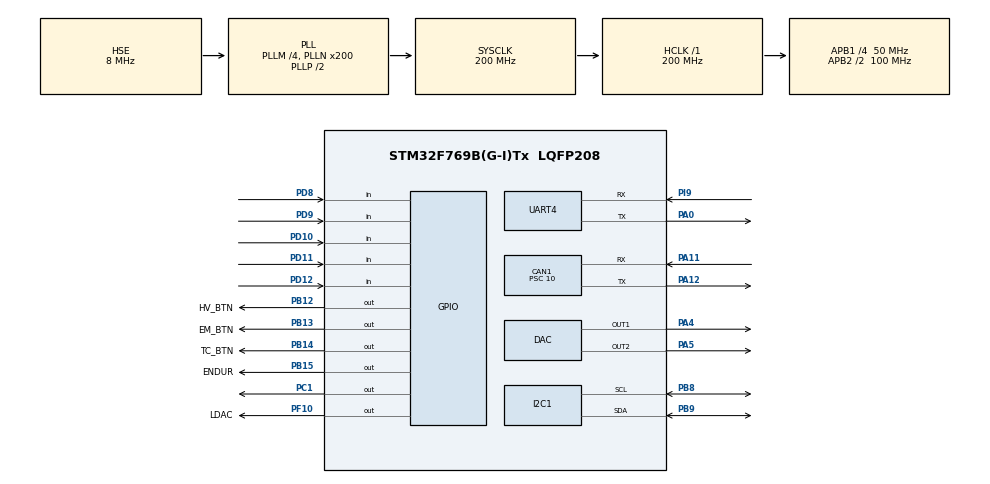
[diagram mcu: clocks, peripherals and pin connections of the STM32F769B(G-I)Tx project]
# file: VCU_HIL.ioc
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CAN1.ABOM=ENABLE
CAN1.AWUM=ENABLE
CAN1.BS1=CAN_BS1_8TQ
CAN1.CalculateBaudRate=500000
CAN1.CalculateTimeBit=2000
CAN1.CalculateTimeQuantum=200.0
CAN1.Prescaler=10
CORTEX_M7.default_mode_Activation=1
FREERTOS.Tasks01=defaultTask,0,128,StartDefaultTask,Default,NULL,Dynamic,NULL,NULL
FREERTOS.configTOTAL_HEAP_SIZE=131072
I2C1.Timing=0x00C0EAFF
Mcu.Family=STM32F7
Mcu.Name=STM32F769B(G-I)Tx
Mcu.Package=LQFP208
NVIC.PriorityGroup=NVIC_PRIORITYGROUP_4
NVIC.TIM1_UP_TIM10_IRQn=true\:15\:0\:false\:false\:true\:false\:false\:true\:true
NVIC.TimeBase=TIM1_UP_TIM10_IRQn
NVIC.TimeBaseIP=TIM1
PA0/WKUP.Mode=Asynchronous
PA0/WKUP.Signal=UART4_TX
PA11.Mode=CAN_Activate
PA11.Signal=CAN1_RX
PA12.Mode=CAN_Activate
PA12.Signal=CAN1_TX
PA4.Signal=COMP_DAC1_group
PA5.Signal=COMP_DAC2_group
PB12.GPIO_Label=HV_BTN
PB12.Signal=GPIO_Output
PB13.GPIO_Label=EM_BTN
PB13.Signal=GPIO_Output
PB14.GPIO_Label=TC_BTN
PB14.Signal=GPIO_Output
PB15.GPIO_Label=ENDUR
PB15.Signal=GPIO_Output
PB8.Mode=I2C
PB8.Signal=I2C1_SCL
PB9.Mode=I2C
PB9.Signal=I2C1_SDA
PC1.Signal=GPIO_Output
PD10.Signal=GPIO_Input
PD11.Signal=GPIO_Input
PD12.Signal=GPIO_Input
PD8.Signal=GPIO_Input
PD9.Signal=GPIO_Input
PF10.GPIO_Label=LDAC
PF10.Signal=GPIO_Output
PH0/OSC_IN.Mode=HSE-External-Oscillator
PH0/OSC_IN.Signal=RCC_OSC_IN
PH1/OSC_OUT.Mode=HSE-External-Oscillator
PH1/OSC_OUT.Signal=RCC_OSC_OUT
PI9.Mode=Asynchronous
PI9.Signal=UART4_RX
ProjectManager.HeapSize=0x200
ProjectManager.StackSize=0x400
ProjectManager.TargetToolchain=Makefile
RCC.AHBFreq_Value=200000000
RCC.APB1CLKDivider=RCC_HCLK_DIV4
RCC.APB1Freq_Value=50000000
RCC.APB1TimFreq_Value=100000000
RCC.APB2CLKDivider=RCC_HCLK_DIV2
RCC.APB2Freq_Value=100000000
RCC.APB2TimFreq_Value=200000000
RCC.CortexFreq_Value=200000000
RCC.HCLKFreq_Value=200000000
RCC.HSE_VALUE=8000000
RCC.HSI_VALUE=16000000
RCC.LSE_VALUE=32768
RCC.PLLM=4
RCC.PLLN=200
RCC.PLLSourceVirtual=RCC_PLLSOURCE_HSE
RCC.SYSCLKFreq_VALUE=200000000
RCC.SYSCLKSource=RCC_SYSCLKSOURCE_PLLCLK
RCC.USBFreq_Value=200000000
RCC.VCOOutputFreq_Value=400000000
SH.COMP_DAC1_group.0=DAC_OUT1,DAC_OUT1
SH.COMP_DAC2_group.0=DAC_OUT2,DAC_OUT2
VP_FREERTOS_VS_CMSIS_V1.Mode=CMSIS_V1
VP_SYS_VS_tim1.Mode=TIM1
board=custom

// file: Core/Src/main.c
/* USER CODE BEGIN Header */
/**
  ******************************************************************************
  * @file           : main.c
  * @brief          : Main program body
  ******************************************************************************
  * @attention
  *
  * Copyright (c) 2025 STMicroelectronics.
  * All rights reserved.
  *
  * This software is licensed under terms that can be found in the LICENSE file
  * in the root directory of this software component.
  * If no LICENSE file comes with this software, it is provided AS-IS.
  *
  ******************************************************************************
  */
/* USER CODE END Header */
#include "main.h"
#include "cmsis_os.h"
#include "can.h"
#include "dac.h"
#include "i2c.h"
#include "usart.h"
#include "gpio.h"
#include "user.h"

void SystemClock_Config(void);
static void MPU_Config(void);
void MX_FREERTOS_Init(void);

int main(void)
{

  /* MPU Configuration--------------------------------------------------------*/
  MPU_Config();

  /* MCU Configuration--------------------------------------------------------*/

  /* Reset of all peripherals, Initializes the Flash interface and the Systick. */
  HAL_Init();

  /* Configure the system clock */
  SystemClock_Config();

  /* Initialize all configured peripherals */
  MX_GPIO_Init();
  MX_CAN1_Init();
  MX_DAC_Init();
  MX_I2C1_Init();
  MX_UART4_Init();
  /* USER CODE BEGIN 2 */
  userInit();
  HAL_CAN_Start(&hcan1);
  HAL_CAN_ActivateNotification(&hcan1, CAN_IT_RX_FIFO0_MSG_PENDING);
  /* USER CODE END 2 */

  /* Call init function for freertos objects (in cmsis_os2.c) */
  MX_FREERTOS_Init();

  /* Start scheduler */
  osKernelStart();

  /* We should never get here as control is now taken by the scheduler */

  /* Infinite loop */
  while (1)
  {

  }
}

void SystemClock_Config(void)
{
  RCC_OscInitTypeDef RCC_OscInitStruct = {0};
  RCC_ClkInitTypeDef RCC_ClkInitStruct = {0};

  /** Configure the main internal regulator output voltage
  */
  __HAL_RCC_PWR_CLK_ENABLE();
  __HAL_PWR_VOLTAGESCALING_CONFIG(PWR_REGULATOR_VOLTAGE_SCALE1);

  /** Initializes the RCC Oscillators according to the specified parameters
  * in the RCC_OscInitTypeDef structure.
  */
  RCC_OscInitStruct.OscillatorType = RCC_OSCILLATORTYPE_HSE;
  RCC_OscInitStruct.HSEState = RCC_HSE_ON;
  RCC_OscInitStruct.PLL.PLLState = RCC_PLL_ON;
  RCC_OscInitStruct.PLL.PLLSource = RCC_PLLSOURCE_HSE;
  RCC_OscInitStruct.PLL.PLLM = 4;
  RCC_OscInitStruct.PLL.PLLN = 200;
  RCC_OscInitStruct.PLL.PLLP = RCC_PLLP_DIV2;
  RCC_OscInitStruct.PLL.PLLQ = 2;
  RCC_OscInitStruct.PLL.PLLR = 2;
  if (HAL_RCC_OscConfig(&RCC_OscInitStruct) != HAL_OK)
  {
    Error_Handler();
  }

  /** Activate the Over-Drive mode
  */
  if (HAL_PWREx_EnableOverDrive() != HAL_OK)
  {
    Error_Handler();
  }

  /** Initializes the CPU, AHB and APB buses clocks
  */
  RCC_ClkInitStruct.ClockType = RCC_CLOCKTYPE_HCLK|RCC_CLOCKTYPE_SYSCLK
                              |RCC_CLOCKTYPE_PCLK1|RCC_CLOCKTYPE_PCLK2;
  RCC_ClkInitStruct.SYSCLKSource = RCC_SYSCLKSOURCE_PLLCLK;
  RCC_ClkInitStruct.AHBCLKDivider = RCC_SYSCLK_DIV1;
  RCC_ClkInitStruct.APB1CLKDivider = RCC_HCLK_DIV4;
  RCC_ClkInitStruct.APB2CLKDivider = RCC_HCLK_DIV2;

  if (HAL_RCC_ClockConfig(&RCC_ClkInitStruct, FLASH_LATENCY_6) != HAL_OK)
  {
    Error_Handler();
  }
}

 /* MPU Configuration */

void MPU_Config(void)
{
  MPU_Region_InitTypeDef MPU_InitStruct = {0};

  /* Disables the MPU */
  HAL_MPU_Disable();

  /** Initializes and configures the Region and the memory to be protected
  */
  MPU_InitStruct.Enable = MPU_REGION_ENABLE;
  MPU_InitStruct.Number = MPU_REGION_NUMBER0;
  MPU_InitStruct.BaseAddress = 0x0;
  MPU_InitStruct.Size = MPU_REGION_SIZE_4GB;
  MPU_InitStruct.SubRegionDisable = 0x87;
  MPU_InitStruct.TypeExtField = MPU_TEX_LEVEL0;
  MPU_InitStruct.AccessPermission = MPU_REGION_NO_ACCESS;
  MPU_InitStruct.DisableExec = MPU_INSTRUCTION_ACCESS_DISABLE;
  MPU_InitStruct.IsShareable = MPU_ACCESS_SHAREABLE;
  MPU_InitStruct.IsCacheable = MPU_ACCESS_NOT_CACHEABLE;
  MPU_InitStruct.IsBufferable = MPU_ACCESS_NOT_BUFFERABLE;

  HAL_MPU_ConfigRegion(&MPU_InitStruct);
  /* Enables the MPU */
  HAL_MPU_Enable(MPU_PRIVILEGED_DEFAULT);

}

void HAL_TIM_PeriodElapsedCallback(TIM_HandleTypeDef *htim)
{
  if (htim->Instance == TIM1)
  {
    HAL_IncTick();
  }
}

void Error_Handler(void)
{
  __disable_irq();
  while (1)
  {
  }
}

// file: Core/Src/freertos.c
/* USER CODE BEGIN Header */
/**
  ******************************************************************************
  * File Name          : freertos.c
  * Description        : Code for freertos applications
  ******************************************************************************
  * @attention
  *
  * Copyright (c) 2025 STMicroelectronics.
  * All rights reserved.
  *
  * This software is licensed under terms that can be found in the LICENSE file
  * in the root directory of this software component.
  * If no LICENSE file comes with this software, it is provided AS-IS.
  *
  ******************************************************************************
  */
/* USER CODE END Header */

#include "FreeRTOS.h"
#include "task.h"
#include "main.h"
#include "cmsis_os.h"

osThreadId defaultTaskHandle;
osThreadId ButtontaskHandle;
osThreadId BrakePressureHandle;
osThreadId BrakePositionHandle;
osThreadId ThrottleHandle;
osThreadId SteeringHandle;

void StartDefaultTask(void const * argument);
extern void ButtonTask(void const * argument);
extern void BrakePressureTask(void const * argument);
extern void BrakePositionTask(void const * argument);
extern void ThrottleTask(void const * argument);
extern void SteeringTask(void const * argument);

void MX_FREERTOS_Init(void); /* (MISRA C 2004 rule 8.1) */

/* GetIdleTaskMemory prototype (linked to static allocation support) */
void vApplicationGetIdleTaskMemory( StaticTask_t **ppxIdleTaskTCBBuffer, StackType_t **ppxIdleTaskStackBuffer, uint32_t *pulIdleTaskStackSize );

/* USER CODE BEGIN GET_IDLE_TASK_MEMORY */
static StaticTask_t xIdleTaskTCBBuffer;
static StackType_t xIdleStack[configMINIMAL_STACK_SIZE];

void vApplicationGetIdleTaskMemory( StaticTask_t **ppxIdleTaskTCBBuffer, StackType_t **ppxIdleTaskStackBuffer, uint32_t *pulIdleTaskStackSize )
{
  *ppxIdleTaskTCBBuffer = &xIdleTaskTCBBuffer;
  *ppxIdleTaskStackBuffer = &xIdleStack[0];
  *pulIdleTaskStackSize = configMINIMAL_STACK_SIZE;
  /* place for user code */
}
/* USER CODE END GET_IDLE_TASK_MEMORY */

void MX_FREERTOS_Init(void) {

  /* Create the thread(s) */
  /* definition and creation of defaultTask */
  osThreadDef(defaultTask, StartDefaultTask, osPriorityNormal, 0, 128);
  defaultTaskHandle = osThreadCreate(osThread(defaultTask), NULL);

  /* definition and creation of Buttontask */
  osThreadDef(Buttontask, ButtonTask, osPriorityNormal, 0, 1000);
  ButtontaskHandle = osThreadCreate(osThread(Buttontask), NULL);

  /* definition and creation of BrakePressure */
  osThreadDef(BrakePressure, BrakePressureTask, osPriorityNormal, 0, 1000);
  BrakePressureHandle = osThreadCreate(osThread(BrakePressure), NULL);

  /* definition and creation of BrakePosition */
  osThreadDef(BrakePosition, BrakePositionTask, osPriorityNormal, 0, 1000);
  BrakePositionHandle = osThreadCreate(osThread(BrakePosition), NULL);

  /* definition and creation of Throttle */
  osThreadDef(Throttle, ThrottleTask, osPriorityNormal, 0, 1000);
  ThrottleHandle = osThreadCreate(osThread(Throttle), NULL);

  /* definition and creation of Steering */
  osThreadDef(Steering, SteeringTask, osPriorityNormal, 0, 1000);
  SteeringHandle = osThreadCreate(osThread(Steering), NULL);

}

void StartDefaultTask(void const * argument)
{
  for(;;)
  {
    osDelay(1);
  }
}
